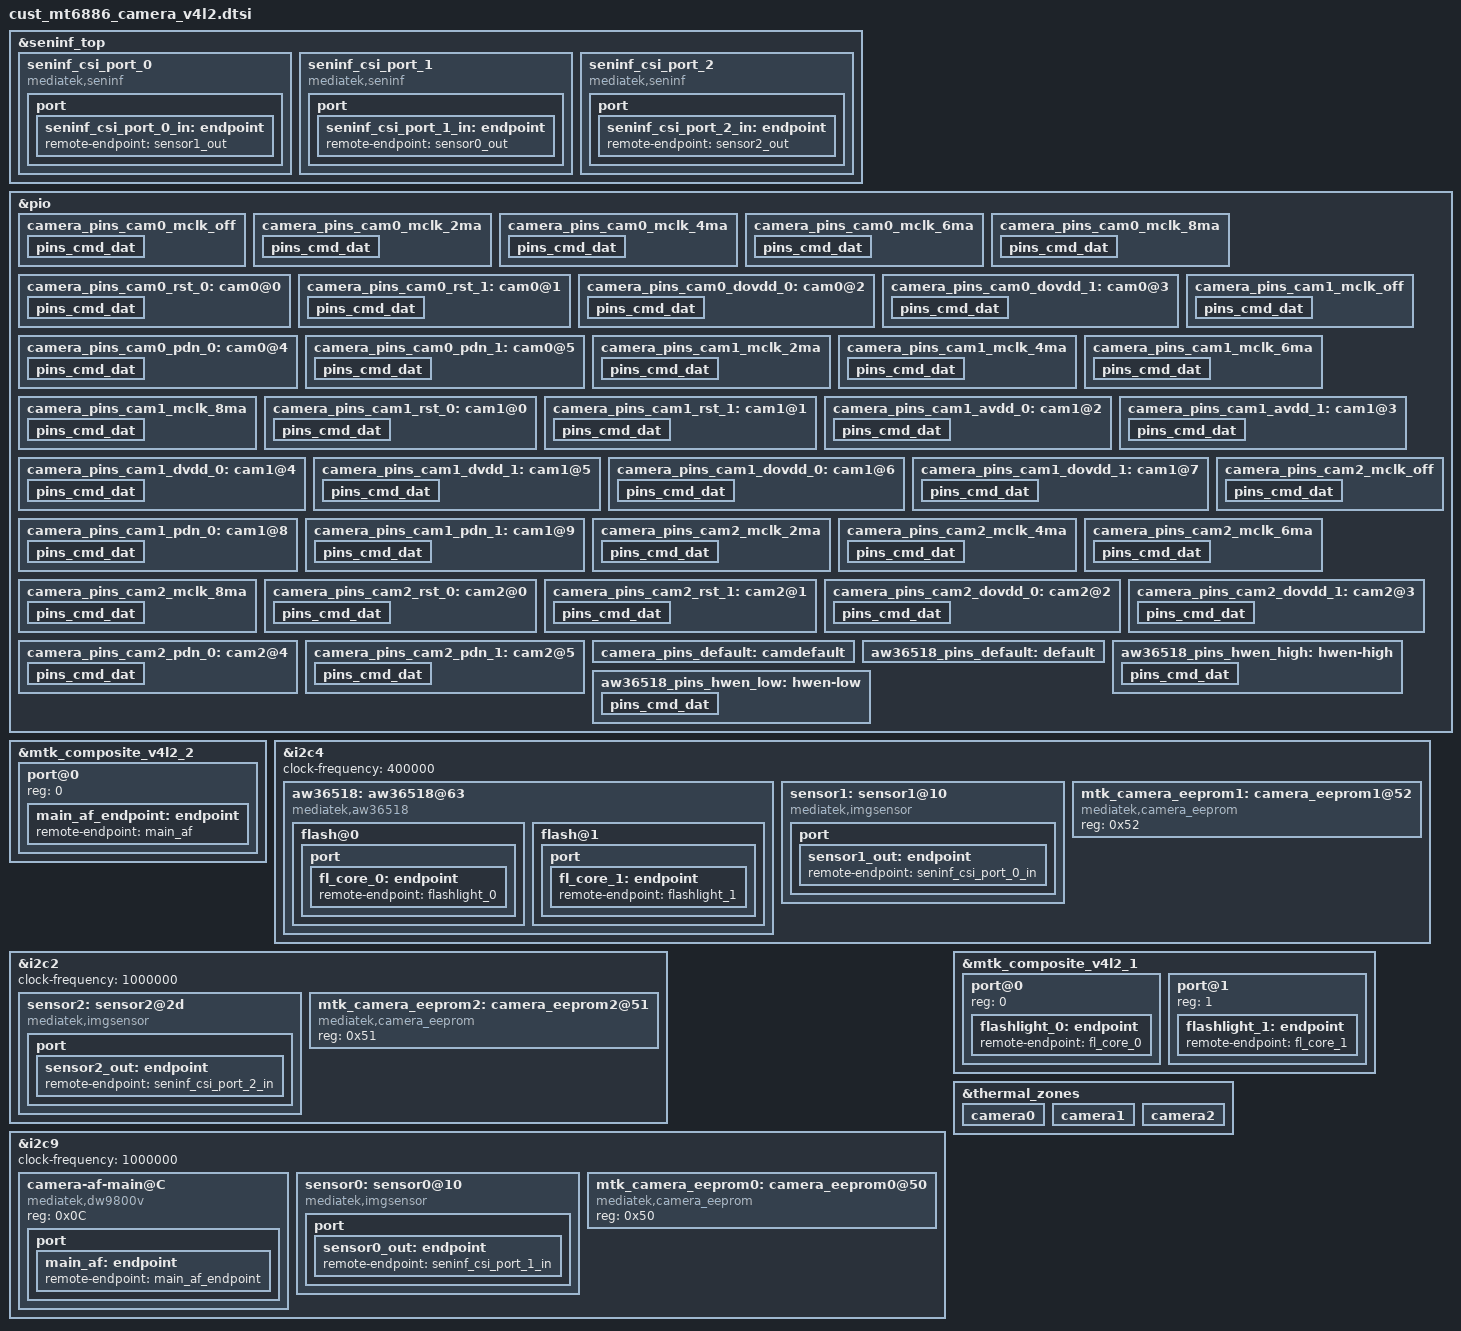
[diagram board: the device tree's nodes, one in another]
// SPDX-License-Identifier: GPL-2.0
/* Copyright (c) 2020 MediaTek Inc. */
#include <dt-bindings/clock/mt6886-clk.h>

&seninf_top {
		seninf_csi_port_0: seninf_csi_port_0 {
			compatible = "mediatek,seninf";
			csi-port = "0";
			dphy_settle_delay_dt = <17>;

			nvmem-cells = <&csi_efuse0>;
			nvmem-cell-names = "rg_csi";

			port {
				seninf_csi_port_0_in: endpoint {
					remote-endpoint = <&sensor1_out>;
				};
			};
		};

		seninf_csi_port_1: seninf_csi_port_1 {
			compatible = "mediatek,seninf";
			csi-port = "1";
			hs_trail_parameter = <0x20>;

			nvmem-cells = <&csi_efuse1>;
			nvmem-cell-names = "rg_csi";

			port {
				seninf_csi_port_1_in: endpoint {
					remote-endpoint = <&sensor0_out>;
				};
			};
		};

		seninf_csi_port_2: seninf_csi_port_2 {
			compatible = "mediatek,seninf";
			csi-port = "2";
			hs_trail_parameter = <0x20>;

			nvmem-cells = <&csi_efuse2>;
			nvmem-cell-names = "rg_csi";

			port {
				seninf_csi_port_2_in: endpoint {
					remote-endpoint = <&sensor2_out>;
				};
			};
		};
};

/* CAMERA GPIO standardization */
&pio {
	camera_pins_cam0_mclk_off: camera_pins_cam0_mclk_off {
		pins_cmd_dat {
			pinmux = <PINMUX_GPIO169__FUNC_GPIO169>;
			drive-strength = <1>;
		};
	};
	camera_pins_cam0_mclk_2ma: camera_pins_cam0_mclk_2ma {
		pins_cmd_dat {
			pinmux = <PINMUX_GPIO169__FUNC_CMMCLK1>;
			drive-strength = <0>;
		};
	};
	camera_pins_cam0_mclk_4ma: camera_pins_cam0_mclk_4ma {
		pins_cmd_dat {
			pinmux = <PINMUX_GPIO169__FUNC_CMMCLK1>;
			drive-strength = <1>;
		};
	};
	camera_pins_cam0_mclk_6ma: camera_pins_cam0_mclk_6ma {
		pins_cmd_dat {
			pinmux = <PINMUX_GPIO169__FUNC_CMMCLK1>;
			drive-strength = <2>;
		};
	};
	camera_pins_cam0_mclk_8ma: camera_pins_cam0_mclk_8ma {
		pins_cmd_dat {
			pinmux = <PINMUX_GPIO169__FUNC_CMMCLK1>;
			drive-strength = <3>;
		};
	};
	camera_pins_cam0_rst_0: cam0@0 {
		pins_cmd_dat {
			pinmux = <PINMUX_GPIO164__FUNC_GPIO164>;
			slew-rate = <1>;
			output-low;
		};
	};
	camera_pins_cam0_rst_1: cam0@1 {
		pins_cmd_dat {
			pinmux = <PINMUX_GPIO164__FUNC_GPIO164>;
			slew-rate = <1>;
			output-high;
		};
	};
	camera_pins_cam0_dovdd_0: cam0@2 {
		pins_cmd_dat {
			pinmux = <PINMUX_GPIO186__FUNC_GPIO186>;
			slew-rate = <1>;
			output-low;
		};
	};
	camera_pins_cam0_dovdd_1: cam0@3 {
		pins_cmd_dat {
			pinmux = <PINMUX_GPIO186__FUNC_GPIO186>;
			slew-rate = <1>;
			output-high;
		};
	};

	camera_pins_cam0_pdn_0: cam0@4 {
		pins_cmd_dat {
			pinmux = <PINMUX_GPIO88__FUNC_GPIO88>;
			slew-rate = <1>;
			output-low;
		};
	};
	camera_pins_cam0_pdn_1: cam0@5 {
		pins_cmd_dat {
			pinmux = <PINMUX_GPIO88__FUNC_GPIO88>;
			slew-rate = <1>;
			output-high;
		};
	};
	camera_pins_cam1_mclk_off: camera_pins_cam1_mclk_off {
		pins_cmd_dat {
			pinmux = <PINMUX_GPIO172__FUNC_GPIO172>;
			drive-strength = <1>;
		};
	};
	camera_pins_cam1_mclk_2ma: camera_pins_cam1_mclk_2ma {
		pins_cmd_dat {
			pinmux = <PINMUX_GPIO172__FUNC_CMMCLK4>;
			drive-strength = <0>;
		};
	};
	camera_pins_cam1_mclk_4ma: camera_pins_cam1_mclk_4ma {
		pins_cmd_dat {
			pinmux = <PINMUX_GPIO172__FUNC_CMMCLK4>;
			drive-strength = <1>;
		};
	};
	camera_pins_cam1_mclk_6ma: camera_pins_cam1_mclk_6ma {
		pins_cmd_dat {
			pinmux = <PINMUX_GPIO172__FUNC_CMMCLK4>;
			drive-strength = <2>;
		};
	};
	camera_pins_cam1_mclk_8ma: camera_pins_cam1_mclk_8ma {
		pins_cmd_dat {
			pinmux = <PINMUX_GPIO172__FUNC_CMMCLK4>;
			drive-strength = <3>;
		};
	};
	camera_pins_cam1_rst_0: cam1@0 {
		pins_cmd_dat {
			pinmux = <PINMUX_GPIO162__FUNC_GPIO162>;
			slew-rate = <1>;
			output-low;
		};
	};
	camera_pins_cam1_rst_1: cam1@1 {
		pins_cmd_dat {
			pinmux = <PINMUX_GPIO162__FUNC_GPIO162>;
			slew-rate = <1>;
			output-high;
		};
	};
	camera_pins_cam1_avdd_0: cam1@2 {
		pins_cmd_dat {
		//front camera bringup
		// front camera bringup.@{
			pinmux = <PINMUX_GPIO156__FUNC_GPIO156>;
		//@}
			slew-rate = <1>;
			output-low;
		};
	};
	camera_pins_cam1_avdd_1: cam1@3 {
		pins_cmd_dat {
		//front camera bringup
		// front camera bringup.@{
			pinmux = <PINMUX_GPIO156__FUNC_GPIO156>;
		//@}
			slew-rate = <1>;
			output-high;
		};
	};
	camera_pins_cam1_dvdd_0: cam1@4 {
		pins_cmd_dat {
			pinmux = <PINMUX_GPIO157__FUNC_GPIO157>;
			slew-rate = <1>;
			output-low;
		};
	};
	camera_pins_cam1_dvdd_1: cam1@5 {
		pins_cmd_dat {
			pinmux = <PINMUX_GPIO157__FUNC_GPIO157>;
			slew-rate = <1>;
			output-high;
		};
	};
	camera_pins_cam1_dovdd_0: cam1@6 {
		pins_cmd_dat {
			pinmux = <PINMUX_GPIO186__FUNC_GPIO186>;
			slew-rate = <1>;
			output-low;
		};
	};
	camera_pins_cam1_dovdd_1: cam1@7 {
		pins_cmd_dat {
			pinmux = <PINMUX_GPIO186__FUNC_GPIO186>;
			slew-rate = <1>;
			output-high;
		};
	};
	camera_pins_cam1_pdn_0: cam1@8 {
		pins_cmd_dat {
			pinmux = <PINMUX_GPIO88__FUNC_GPIO88>;
			slew-rate = <1>;
			output-low;
		};
	};
	camera_pins_cam1_pdn_1: cam1@9 {
		pins_cmd_dat {
			pinmux = <PINMUX_GPIO88__FUNC_GPIO88>;
			slew-rate = <1>;
			output-high;
		};
	};

	camera_pins_cam2_mclk_off: camera_pins_cam2_mclk_off {
		pins_cmd_dat {
			pinmux = <PINMUX_GPIO170__FUNC_GPIO170>;
			drive-strength = <1>;
		};
	};
	camera_pins_cam2_mclk_2ma: camera_pins_cam2_mclk_2ma {
		pins_cmd_dat {
			pinmux = <PINMUX_GPIO170__FUNC_CMMCLK2>;
			drive-strength = <0>;
		};
	};
	camera_pins_cam2_mclk_4ma: camera_pins_cam2_mclk_4ma {
		pins_cmd_dat {
			pinmux = <PINMUX_GPIO170__FUNC_CMMCLK2>;
			drive-strength = <1>;
		};
	};
	camera_pins_cam2_mclk_6ma: camera_pins_cam2_mclk_6ma {
		pins_cmd_dat {
			pinmux = <PINMUX_GPIO170__FUNC_CMMCLK2>;
			drive-strength = <2>;
		};
	};
	camera_pins_cam2_mclk_8ma: camera_pins_cam2_mclk_8ma {
		pins_cmd_dat {
			pinmux = <PINMUX_GPIO170__FUNC_CMMCLK2>;
			drive-strength = <3>;
		};
	};
	camera_pins_cam2_rst_0: cam2@0 {
		pins_cmd_dat {
			pinmux = <PINMUX_GPIO163__FUNC_GPIO163>;
			slew-rate = <1>;
			output-low;
		};
	};
	camera_pins_cam2_rst_1: cam2@1 {
		pins_cmd_dat {
			pinmux = <PINMUX_GPIO163__FUNC_GPIO163>;
			slew-rate = <1>;
			output-high;
		};
	};

	camera_pins_cam2_dovdd_0: cam2@2{
		pins_cmd_dat {
			pinmux = <PINMUX_GPIO186__FUNC_GPIO186>;
			slew-rate = <1>;
			output-low;
		};
	};
	camera_pins_cam2_dovdd_1: cam2@3{
		pins_cmd_dat {
			pinmux = <PINMUX_GPIO186__FUNC_GPIO186>;
			slew-rate = <1>;
			output-high;
		};
	};

	camera_pins_cam2_pdn_0: cam2@4 {
		pins_cmd_dat {
			pinmux = <PINMUX_GPIO88__FUNC_GPIO88>;
			slew-rate = <1>;
			output-low;
		};
	};
	camera_pins_cam2_pdn_1: cam2@5 {
		pins_cmd_dat {
			pinmux = <PINMUX_GPIO88__FUNC_GPIO88>;
			slew-rate = <1>;
			output-high;
		};
	};

	camera_pins_default: camdefault {
	};
};
/* CAMERA GPIO end */

&mtk_composite_v4l2_2 {
	#address-cells = <1>;
	#size-cells = <0>;
	port@0 {
		reg = <0>;
		main_af_endpoint: endpoint {
			remote-endpoint = <&main_af>;
		};
	};
};

&i2c4 {
	aw36518:aw36518@63 {
		compatible = "mediatek,aw36518";
		reg = <0x63>;
		pinctrl-names = "default", "hwen-high", "hwen-low";
		pinctrl-0 = <&aw36518_pins_default>;
		pinctrl-1 = <&aw36518_pins_hwen_high>;
		pinctrl-2 = <&aw36518_pins_hwen_low>;
		status = "okay";
		flash@0{
			reg = <0>;
			type = <0>;
			ct = <0>;
			part = <0>;
			port {
				fl_core_0: endpoint {
					remote-endpoint = <&flashlight_0>;
				};
			};
		};
		flash@1{
			reg = <1>;
			type = <0>;
			ct = <1>;
			part = <0>;
			port {
				fl_core_1: endpoint {
					remote-endpoint = <&flashlight_1>;
				};
			};
		};
	};
};

&i2c2 {
	status = "okay";
	clock-frequency = <1000000>;
	#address-cells = <1>;
	#size-cells = <0>;

	sensor2: sensor2@2d {
		compatible = "mediatek,imgsensor";
		sensor-names = "s5kjn1_mipi_raw";
		reg = <0x2d>;
		#thermal-sensor-cells = <0>;

		pinctrl-names = "mclk_off",
				"mclk_2mA",
				"mclk_4mA",
				"mclk_6mA",
				"mclk_8mA",
				"rst_low",
				"rst_high",
				"dovdd_off",
				"dovdd_on",
				"pdn_low",
				"pdn_high";
		pinctrl-0 = <&camera_pins_cam2_mclk_off>;
		pinctrl-1 = <&camera_pins_cam2_mclk_2ma>;
		pinctrl-2 = <&camera_pins_cam2_mclk_4ma>;
		pinctrl-3 = <&camera_pins_cam2_mclk_6ma>;
		pinctrl-4 = <&camera_pins_cam2_mclk_8ma>;
		pinctrl-5 = <&camera_pins_cam2_rst_0>;
		pinctrl-6 = <&camera_pins_cam2_rst_1>;
		pinctrl-7 = <&camera_pins_cam2_dovdd_0>;
		pinctrl-8 = <&camera_pins_cam2_dovdd_1>;
		pinctrl-9 = <&camera_pins_cam2_pdn_0>;
		pinctrl-10 = <&camera_pins_cam2_pdn_1>;

		avdd-supply = <&wl2868c_ldo6>;
		dvdd1-supply = <&wl2868c_ldo2>;

		clocks = <&topckgen_clk CLK_TOP_UNIVPLL_192M_D32>,
			<&topckgen_clk CLK_TOP_UNIVPLL_192M_D16>,
			<&topckgen_clk CLK_TOP_F26M_CK_D2>,
			<&topckgen_clk CLK_TOP_UNIVPLL_192M_D10>,
			<&topckgen_clk CLK_TOP_UNIVPLL_192M_D8>,
			<&topckgen_clk CLK_TOP_TCK_26M_MX9>,
			<&topckgen_clk CLK_TOP_UNIVPLL_D6_D8>,
			<&topckgen_clk CLK_TOP_CAMTG3_SEL>;
		clock-names = "6", "12", "13", "19.2", "24", "26", "52", "mclk";


		status = "okay";

		port {
			sensor2_out: endpoint {
				remote-endpoint = <&seninf_csi_port_2_in>;
			};
		};
	};

	mtk_camera_eeprom2:camera_eeprom2@51 {
		compatible = "mediatek,camera_eeprom";
		reg = <0x51>;
		status = "okay";
	};
};

&i2c4 {
	status = "okay";
	clock-frequency = <400000>;
	#address-cells = <1>;
	#size-cells = <0>;

	sensor1: sensor1@10 {
		compatible = "mediatek,imgsensor";
		sensor-names = "imx615_mipi_raw";
		reg = <0x10>;
		#thermal-sensor-cells = <0>;

		pinctrl-names = "mclk_off",
				"mclk_2mA",
				"mclk_4mA",
				"mclk_6mA",
				"mclk_8mA",
				"rst_low",
				"rst_high",
				"avdd_off",
				"avdd_on",
				"dvdd_off",
				"dvdd_on",
				"dovdd_off",
				"dovdd_on",
				"pdn_low",
				"pdn_high";
		pinctrl-0 = <&camera_pins_cam1_mclk_off>;
		pinctrl-1 = <&camera_pins_cam1_mclk_2ma>;
		pinctrl-2 = <&camera_pins_cam1_mclk_4ma>;
		pinctrl-3 = <&camera_pins_cam1_mclk_6ma>;
		pinctrl-4 = <&camera_pins_cam1_mclk_8ma>;
		pinctrl-5 = <&camera_pins_cam1_rst_0>;
		pinctrl-6 = <&camera_pins_cam1_rst_1>;
		pinctrl-7 = <&camera_pins_cam1_avdd_0>;
		pinctrl-8 = <&camera_pins_cam1_avdd_1>;
		pinctrl-9 = <&camera_pins_cam1_dvdd_0>;
		pinctrl-10 = <&camera_pins_cam1_dvdd_1>;
		pinctrl-11 = <&camera_pins_cam1_dovdd_0>;
		pinctrl-12 = <&camera_pins_cam1_dovdd_1>;
		pinctrl-13 = <&camera_pins_cam1_pdn_0>;
		pinctrl-14 = <&camera_pins_cam1_pdn_1>;

		clocks = <&topckgen_clk CLK_TOP_UNIVPLL_192M_D32>,
			<&topckgen_clk CLK_TOP_UNIVPLL_192M_D16>,
			<&topckgen_clk CLK_TOP_F26M_CK_D2>,
			<&topckgen_clk CLK_TOP_UNIVPLL_192M_D10>,
			<&topckgen_clk CLK_TOP_UNIVPLL_192M_D8>,
			<&topckgen_clk CLK_TOP_TCK_26M_MX9>,
			<&topckgen_clk CLK_TOP_UNIVPLL_D6_D8>,
			<&topckgen_clk CLK_TOP_CAMTG5_SEL>;
		clock-names = "6", "12", "13", "19.2", "24", "26", "52", "mclk";

		status = "okay";

		port {
			sensor1_out: endpoint {
				remote-endpoint = <&seninf_csi_port_0_in>;
			};
		};
	};

	mtk_camera_eeprom1:camera_eeprom1@52 {
		compatible = "mediatek,camera_eeprom";
		reg = <0x52>;
		status = "okay";
	};
};

&i2c9 {
	status = "okay";
	clock-frequency = <1000000>;
	#address-cells = <1>;
	#size-cells = <0>;

	camera-af-main@C {
		compatible = "mediatek,dw9800v";
		reg = <0x0C>;

		port {
			main_af: endpoint {
				remote-endpoint = <&main_af_endpoint>;
			};
		};
	};

	sensor0: sensor0@10 {
		compatible = "mediatek,imgsensor";
		sensor-names = "s5kgn9_mipi_raw",
		               "s5kgn9stech_mipi_raw";
		reg = <0x10>;
		#thermal-sensor-cells = <0>;



		pinctrl-names = "mclk_off",
				"mclk_2mA",
				"mclk_4mA",
				"mclk_6mA",
				"mclk_8mA",
				"rst_low",
				"rst_high",
				"dovdd_off",
				"dovdd_on",
				"pdn_low",
				"pdn_high";
		pinctrl-0 = <&camera_pins_cam0_mclk_off>;
		pinctrl-1 = <&camera_pins_cam0_mclk_2ma>;
		pinctrl-2 = <&camera_pins_cam0_mclk_4ma>;
		pinctrl-3 = <&camera_pins_cam0_mclk_6ma>;
		pinctrl-4 = <&camera_pins_cam0_mclk_8ma>;
		pinctrl-5 = <&camera_pins_cam0_rst_0>;
		pinctrl-6 = <&camera_pins_cam0_rst_1>;
		pinctrl-7 = <&camera_pins_cam0_dovdd_0>;
		pinctrl-8 = <&camera_pins_cam0_dovdd_1>;
		pinctrl-9 = <&camera_pins_cam0_pdn_0>;
		pinctrl-10 = <&camera_pins_cam0_pdn_1>;

		clocks = <&topckgen_clk CLK_TOP_UNIVPLL_192M_D32>,
			<&topckgen_clk CLK_TOP_UNIVPLL_192M_D16>,
			<&topckgen_clk CLK_TOP_F26M_CK_D2>,
			<&topckgen_clk CLK_TOP_UNIVPLL_192M_D10>,
			<&topckgen_clk CLK_TOP_UNIVPLL_192M_D8>,
			<&topckgen_clk CLK_TOP_TCK_26M_MX9>,
			<&topckgen_clk CLK_TOP_UNIVPLL_D6_D8>,
			<&topckgen_clk CLK_TOP_CAMTG2_SEL>;
		clock-names = "6", "12", "13", "19.2", "24", "26", "52", "mclk";

		//dvdd-supply = <&wl2868c_ldo1>;
		//avdd-supply = <&wl2868c_ldo5>;

		status = "okay";

		port {
			sensor0_out: endpoint {
				remote-endpoint = <&seninf_csi_port_1_in>;
			};
		};
	};

    mtk_camera_eeprom0:camera_eeprom0@50 {
            compatible = "mediatek,camera_eeprom";
            reg = <0x50>;
            status = "okay";
    };
};

&pio {
	aw36518_pins_default: default {
	};

	aw36518_pins_hwen_high: hwen-high {
		pins_cmd_dat {
			pinmux = <PINMUX_GPIO90__FUNC_GPIO90>;
			slew-rate = <1>;
			output-high;
		};
	};

	aw36518_pins_hwen_low: hwen-low {
		pins_cmd_dat {
			pinmux = <PINMUX_GPIO90__FUNC_GPIO90>;
			slew-rate = <1>;
			output-low;
		};
	};
};

&mtk_composite_v4l2_1 {
	#address-cells = <1>;
	#size-cells = <0>;
	port@0 {
		reg = <0>;
		flashlight_0: endpoint {
			remote-endpoint = <&fl_core_0>;
		};
	};
	port@1 {
		reg = <1>;
		flashlight_1: endpoint {
			remote-endpoint = <&fl_core_1>;
		};
	};
};


&thermal_zones {
	camera0: camera0 {
		polling-delay = <0>; /* milliseconds */
		polling-delay-passive = <0>; /* milliseconds */
		thermal-sensors = <&sensor0>;
	};
	camera1: camera1 {
		polling-delay = <0>; /* milliseconds */
		polling-delay-passive = <0>; /* milliseconds */
		thermal-sensors = <&sensor1>;
	};
	camera2: camera2 {
		polling-delay = <0>; /* milliseconds */
		polling-delay-passive = <0>; /* milliseconds */
		thermal-sensors = <&sensor2>;
	};
};
